VERSION "HIPBNYYYYYYYYYYYYYYYYYYYYYYYYYYYYYYYYYYYYY/4/%%%/4/'%**4YYY///"

NS_ :

BS_:

BU_:

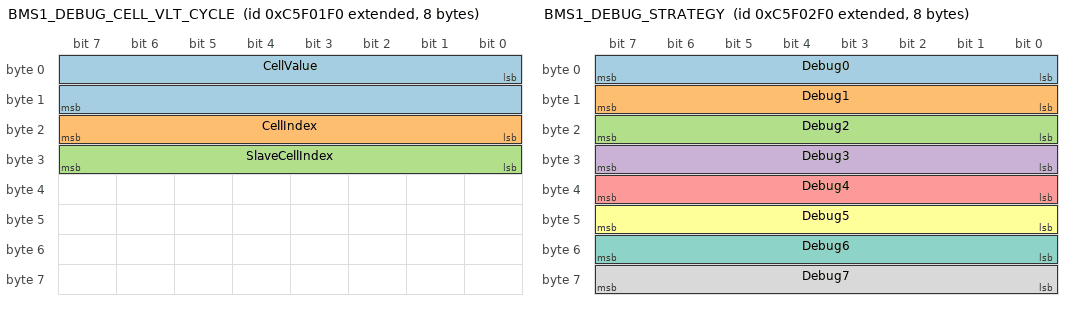
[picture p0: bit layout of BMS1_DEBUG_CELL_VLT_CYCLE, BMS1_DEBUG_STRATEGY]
BO_ 2355036656 BMS1_DEBUG_CELL_VLT_CYCLE: 8 Vector__XXX
 SG_ CellValue : 0|16@1+ (0.0001,0) [0|0] "" Vector__XXX
 SG_ CellIndex : 16|8@1+ (1,0) [0|0] "" Vector__XXX
 SG_ SlaveCellIndex : 24|8@1+ (1,0) [0|0] "" Vector__XXX

BO_ 2355036912 BMS1_DEBUG_STRATEGY: 8 Vector__XXX
 SG_ Debug0 : 0|8@1+ (1,0) [0|0] "" Vector__XXX
 SG_ Debug1 : 8|8@1+ (1,0) [0|0] "" Vector__XXX
 SG_ Debug2 : 16|8@1+ (1,0) [0|0] "" Vector__XXX
 SG_ Debug3 : 24|8@1+ (1,0) [0|0] "" Vector__XXX
 SG_ Debug4 : 32|8@1+ (1,0) [0|0] "" Vector__XXX
 SG_ Debug5 : 40|8@1+ (1,0) [0|0] "" Vector__XXX
 SG_ Debug6 : 48|8@1+ (1,0) [0|0] "" Vector__XXX
 SG_ Debug7 : 56|8@1+ (1,0) [0|0] "" Vector__XXX

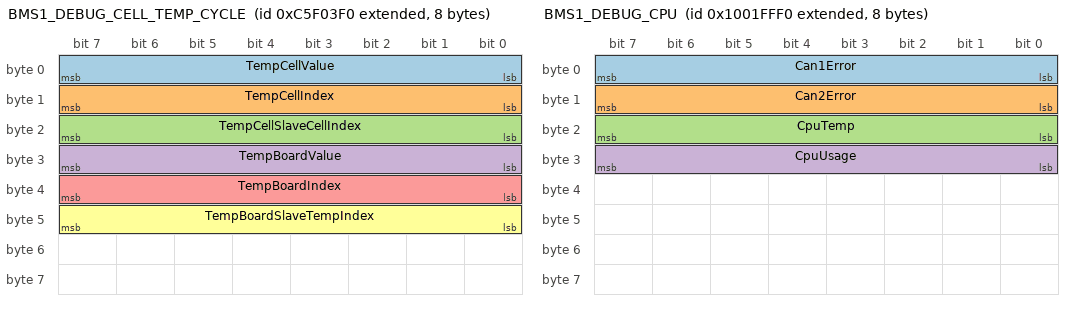
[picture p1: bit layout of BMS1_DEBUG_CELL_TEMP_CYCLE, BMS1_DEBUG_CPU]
BO_ 2355037168 BMS1_DEBUG_CELL_TEMP_CYCLE: 8 Vector__XXX
 SG_ TempCellValue : 0|8@1+ (1,-40) [0|0] "" Vector__XXX
 SG_ TempCellIndex : 8|8@1+ (1,0) [0|0] "" Vector__XXX
 SG_ TempCellSlaveCellIndex : 16|8@1+ (1,0) [0|0] "" Vector__XXX
 SG_ TempBoardValue : 24|8@1+ (1,-40) [0|0] "" Vector__XXX
 SG_ TempBoardIndex : 32|8@1+ (1,0) [0|0] "" Vector__XXX
 SG_ TempBoardSlaveTempIndex : 40|8@1+ (1,0) [0|0] "" Vector__XXX

BO_ 2416050160 BMS1_DEBUG_CPU: 8 Vector__XXX
 SG_ Can1Error : 0|8@1+ (1,0) [0|0] "" Vector__XXX
 SG_ Can2Error : 8|8@1+ (1,0) [0|0] "" Vector__XXX
 SG_ CpuTemp : 16|8@1+ (1,0) [0|0] "" Vector__XXX
 SG_ CpuUsage : 24|8@1+ (1,0) [0|0] "" Vector__XXX

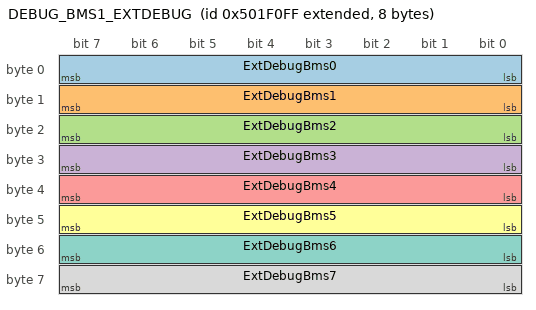
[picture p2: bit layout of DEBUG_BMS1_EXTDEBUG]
BO_ 2231496959 DEBUG_BMS1_EXTDEBUG: 8 Vector__XXX
 SG_ ExtDebugBms0 : 0|8@1+ (1,0) [0|0] "-" Vector__XXX
 SG_ ExtDebugBms1 : 8|8@1+ (1,0) [0|0] "-" Vector__XXX
 SG_ ExtDebugBms2 : 16|8@1+ (1,0) [0|0] "-" Vector__XXX
 SG_ ExtDebugBms3 : 24|8@1+ (1,0) [0|0] "-" Vector__XXX
 SG_ ExtDebugBms4 : 32|8@1+ (1,0) [0|0] "-" Vector__XXX
 SG_ ExtDebugBms5 : 40|8@1+ (1,0) [0|0] "-" Vector__XXX
 SG_ ExtDebugBms6 : 48|8@1+ (1,0) [0|0] "-" Vector__XXX
 SG_ ExtDebugBms7 : 56|8@1+ (1,0) [0|0] "-" Vector__XXX

CM_ SG_ 2355036656 CellValue "CellsValue, debug use";
CM_ SG_ 2355036656 CellIndex "CellIndex, debug use";
CM_ SG_ 2355036656 SlaveCellIndex "ModuleIndex, debug use";
CM_ SG_ 2355036912 Debug0 "Debug Value";
CM_ SG_ 2355036912 Debug1 "Debug Value";
CM_ SG_ 2355036912 Debug2 "Debug Value";
CM_ SG_ 2355036912 Debug3 "Debug Value";
CM_ SG_ 2355036912 Debug4 "Debug Value";
CM_ SG_ 2355036912 Debug5 "Debug Value";
CM_ SG_ 2355036912 Debug6 "Debug Value";
CM_ SG_ 2355036912 Debug7 "Debug Value";
CM_ SG_ 2355037168 TempCellValue "CellsValue, debug use";
CM_ SG_ 2355037168 TempCellIndex "CellIndex, debug use";
CM_ SG_ 2355037168 TempCellSlaveCellIndex "ModuleIndex, debug use";
CM_ SG_ 2355037168 TempBoardValue "TempsValue, debug use";
CM_ SG_ 2355037168 TempBoardIndex "CellIndex, debug use";
CM_ SG_ 2355037168 TempBoardSlaveTempIndex "ModuleIndex, debug use";
CM_ SG_ 2231496959 ExtDebugBms0 "Comment";
CM_ SG_ 2231496959 ExtDebugBms1 "Comment";
CM_ SG_ 2231496959 ExtDebugBms2 "Comment";
CM_ SG_ 2231496959 ExtDebugBms3 "Comment";
CM_ SG_ 2231496959 ExtDebugBms4 "Comment";
CM_ SG_ 2231496959 ExtDebugBms5 "Comment";
CM_ SG_ 2231496959 ExtDebugBms6 "Comment";
CM_ SG_ 2231496959 ExtDebugBms7 "Comment";
BA_DEF_  "BusType" STRING ;
BA_DEF_DEF_  "BusType" "";
BA_ "BusType" "CAN";
